AUTOSAR XML (schema 00046)
package /ComponentTypes
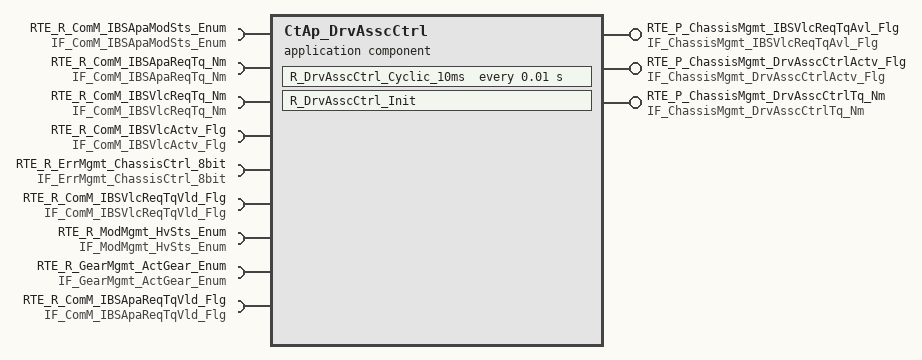
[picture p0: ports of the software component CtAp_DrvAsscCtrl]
  application sw component type CtAp_DrvAsscCtrl
    provide port RTE_P_ChassisMgmt_IBSVlcReqTqAvl_Flg: nonqueued-sender-com-spec{data-element=tec_ChassisMgmt_IBSVlcReqTqAvl_Flg, init-value=0}, provided-interface=IF_ChassisMgmt_IBSVlcReqTqAvl_Flg
    provide port RTE_P_ChassisMgmt_DrvAsscCtrlActv_Flg: nonqueued-sender-com-spec{data-element=tec_ChassisMgmt_DrvAsscCtrlActv_Flg, init-value=0}, provided-interface=IF_ChassisMgmt_DrvAsscCtrlActv_Flg
    provide port RTE_P_ChassisMgmt_DrvAsscCtrlTq_Nm: nonqueued-sender-com-spec{data-element=tec_ChassisMgmt_DrvAsscCtrlTq_Nm, init-value=0}, provided-interface=IF_ChassisMgmt_DrvAsscCtrlTq_Nm
    9 x require port:
      RTE_R_ComM_IBSApaModSts_Enum: nonqueued-receiver-com-spec{data-element=tec_ComM_IBSApaModSts_Enum, filter=data-filter-type=ALWAYS, init-value=0}, required-interface=IF_ComM_IBSApaModSts_Enum
      RTE_R_ComM_IBSApaReqTq_Nm: nonqueued-receiver-com-spec{data-element=tec_ComM_IBSApaReqTq_Nm, filter=data-filter-type=ALWAYS, init-value=0}, required-interface=IF_ComM_IBSApaReqTq_Nm
      RTE_R_ComM_IBSVlcReqTq_Nm: nonqueued-receiver-com-spec{data-element=tec_ComM_IBSVlcReqTq_Nm, filter=data-filter-type=ALWAYS, init-value=0}, required-interface=IF_ComM_IBSVlcReqTq_Nm
      RTE_R_ComM_IBSVlcActv_Flg: nonqueued-receiver-com-spec{data-element=tec_ComM_IBSVlcActv_Flg, filter=data-filter-type=ALWAYS, init-value=0}, required-interface=IF_ComM_IBSVlcActv_Flg
      RTE_R_ErrMgmt_ChassisCtrl_8bit: nonqueued-receiver-com-spec{data-element=tec_ErrMgmt_ChassisCtrl_8bit, filter=data-filter-type=ALWAYS, init-value=0}, required-interface=IF_ErrMgmt_ChassisCtrl_8bit
      RTE_R_ComM_IBSVlcReqTqVld_Flg: nonqueued-receiver-com-spec{data-element=tec_ComM_IBSVlcReqTqVld_Flg, filter=data-filter-type=ALWAYS, init-value=0}, required-interface=IF_ComM_IBSVlcReqTqVld_Flg
      RTE_R_ModMgmt_HvSts_Enum: nonqueued-receiver-com-spec{data-element=tec_ModMgmt_HvSts_Enum, filter=data-filter-type=ALWAYS, init-value=0}, required-interface=IF_ModMgmt_HvSts_Enum
      RTE_R_GearMgmt_ActGear_Enum: nonqueued-receiver-com-spec{data-element=tec_GearMgmt_ActGear_Enum, filter=data-filter-type=ALWAYS, init-value=0}, required-interface=IF_GearMgmt_ActGear_Enum
      RTE_R_ComM_IBSApaReqTqVld_Flg: nonqueued-receiver-com-spec{data-element=tec_ComM_IBSApaReqTqVld_Flg, filter=data-filter-type=ALWAYS, init-value=0}, required-interface=IF_ComM_IBSApaReqTqVld_Flg
    behavior CtAp_DrvAsscCtrl_InternalBehavior
      init event CtAp_DrvAsscCtrl_InitEvent: start-on-event=R_DrvAsscCtrl_Init
      timing event TMT_R_DrvAsscCtrl_Cyclic_10ms: start-on-event=R_DrvAsscCtrl_Cyclic_10ms, period=0.01
      runnable R_DrvAsscCtrl_Init
      runnable R_DrvAsscCtrl_Cyclic_10ms
        data-receive-point-by-arguments:
          9 x access:
            REC_RTE_R_ComM_IBSApaModSts_Enum_tec_ComM_IBSApaModSts_Enum: accessed-variable=RTE_R_ComM_IBSApaModSts_Enum.tec_ComM_IBSApaModSts_Enum
            REC_RTE_R_ComM_IBSApaReqTqVld_Flg_tec_ComM_IBSApaReqTqVld_Flg: accessed-variable=RTE_R_ComM_IBSApaReqTqVld_Flg.tec_ComM_IBSApaReqTqVld_Flg
            REC_RTE_R_ComM_IBSApaReqTq_Nm_tec_ComM_IBSApaReqTq_Nm: accessed-variable=RTE_R_ComM_IBSApaReqTq_Nm.tec_ComM_IBSApaReqTq_Nm
            REC_RTE_R_ComM_IBSVlcActv_Flg_tec_ComM_IBSVlcActv_Flg: accessed-variable=RTE_R_ComM_IBSVlcActv_Flg.tec_ComM_IBSVlcActv_Flg
            REC_RTE_R_ComM_IBSVlcReqTqVld_Flg_tec_ComM_IBSVlcReqTqVld_Flg: accessed-variable=RTE_R_ComM_IBSVlcReqTqVld_Flg.tec_ComM_IBSVlcReqTqVld_Flg
            REC_RTE_R_ComM_IBSVlcReqTq_Nm_tec_ComM_IBSVlcReqTq_Nm: accessed-variable=RTE_R_ComM_IBSVlcReqTq_Nm.tec_ComM_IBSVlcReqTq_Nm
            REC_RTE_R_ErrMgmt_ChassisCtrl_8bit_tec_ErrMgmt_ChassisCtrl_8bit: accessed-variable=RTE_R_ErrMgmt_ChassisCtrl_8bit.tec_ErrMgmt_ChassisCtrl_8bit
            REC_RTE_R_GearMgmt_ActGear_Enum_tec_GearMgmt_ActGear_Enum: accessed-variable=RTE_R_GearMgmt_ActGear_Enum.tec_GearMgmt_ActGear_Enum
            REC_RTE_R_ModMgmt_HvSts_Enum_tec_ModMgmt_HvSts_Enum: accessed-variable=RTE_R_ModMgmt_HvSts_Enum.tec_ModMgmt_HvSts_Enum
        data-send-points:
          access SEND_RTE_P_ChassisMgmt_DrvAsscCtrlActv_Flg_tec_ChassisMgmt_DrvAsscCtrlActv_Flg: accessed-variable=RTE_P_ChassisMgmt_DrvAsscCtrlActv_Flg.tec_ChassisMgmt_DrvAsscCtrlActv_Flg
          access SEND_RTE_P_ChassisMgmt_DrvAsscCtrlTq_Nm_tec_ChassisMgmt_DrvAsscCtrlTq_Nm: accessed-variable=RTE_P_ChassisMgmt_DrvAsscCtrlTq_Nm.tec_ChassisMgmt_DrvAsscCtrlTq_Nm
          access SEND_RTE_P_ChassisMgmt_IBSVlcReqTqAvl_Flg_tec_ChassisMgmt_IBSVlcReqTqAvl_Flg: accessed-variable=RTE_P_ChassisMgmt_IBSVlcReqTqAvl_Flg.tec_ChassisMgmt_IBSVlcReqTqAvl_Flg
  swc implementation CtAp_DrvAsscCtrl_Implementation: behavior=CtAp_DrvAsscCtrl_InternalBehavior
    code-descriptors:
      code Default: artifact-descriptors=autosar-engineering-object=category=SWOBJ
